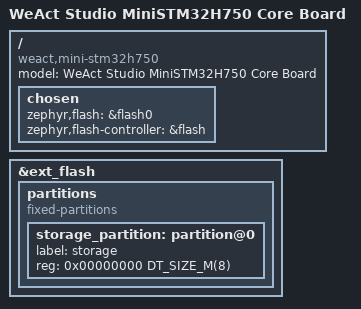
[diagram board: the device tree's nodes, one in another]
/*
 * SPDX-FileCopyrightText: Copyright The Zephyr Project Contributors
 *
 * SPDX-License-Identifier: Apache-2.0
 */

/dts-v1/;
#include "mini_stm32h750-common.dtsi"

/ {
	model = "WeAct Studio MiniSTM32H750 Core Board";
	compatible = "weact,mini-stm32h750";

	chosen {
		zephyr,flash = &flash0;
		zephyr,flash-controller = &flash;
	};
};

&ext_flash {
	status = "okay";

	partitions {
		compatible = "fixed-partitions";
		#address-cells = <1>;
		#size-cells = <1>;

		storage_partition: partition@0 {
			label = "storage";
			reg = <0x00000000 DT_SIZE_M(8)>; /* 8MB */
		};
	};
};
